# f28e12x_adc_lite_result_regs register map
Vendor: Texas Instruments
Peripheral module from a debugger description file (folder C2000).
Address unit: 16 bits
Registers are 16-bit, read-only, no defined reset value unless marked. A register's access mark holds for its fields unless they carry their own. Offsets are as the file gives them; lines under a group give offsets from that group; [hi:lo] are bit positions; {n}, {i} and the like mark numbered series; 'fields as' and 'values as' point back to an identical list; <NAME> marks a mode.

## ADC_LITE_RESULT_REGS — ADC LITE RESULT Registers
{0x0+i} ADCRESULT{i} (i=0..15)
  [11:0] RESULT — ADC Result
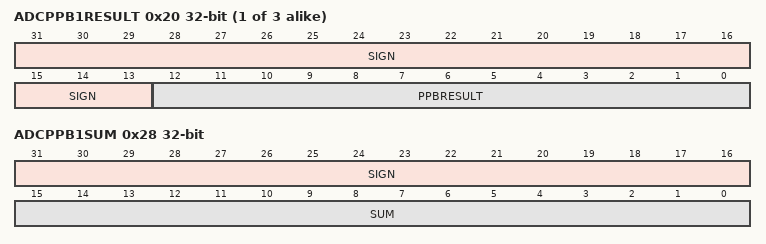
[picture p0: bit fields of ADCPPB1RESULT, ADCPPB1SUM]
{0x1E+2i} ADCPPB{i}RESULT 32-bit (i=1..3) — ADC Post Processing Block {i} Result Register
  [31:13] SIGN — Sign Extended Bits
  [12:0] PPBRESULT — ADC Post Processing Block Result
0x28 ADCPPB1SUM 32-bit — ADC PPB 1 Final Sum Result Register
  [31:16] SIGN — Sign Extended Bits
  [15:0] SUM — Post Processing Block 1 Oversampling Sum
0x2A ADCPPB1COUNT — ADC PPB1 Final Conversion Count Register
  [3:0] COUNT — Post Processing Block 1 Final Count
